AUTOSAR XML (schema 4-2-2)
package /STELLANTIS/EPT/ASWCs
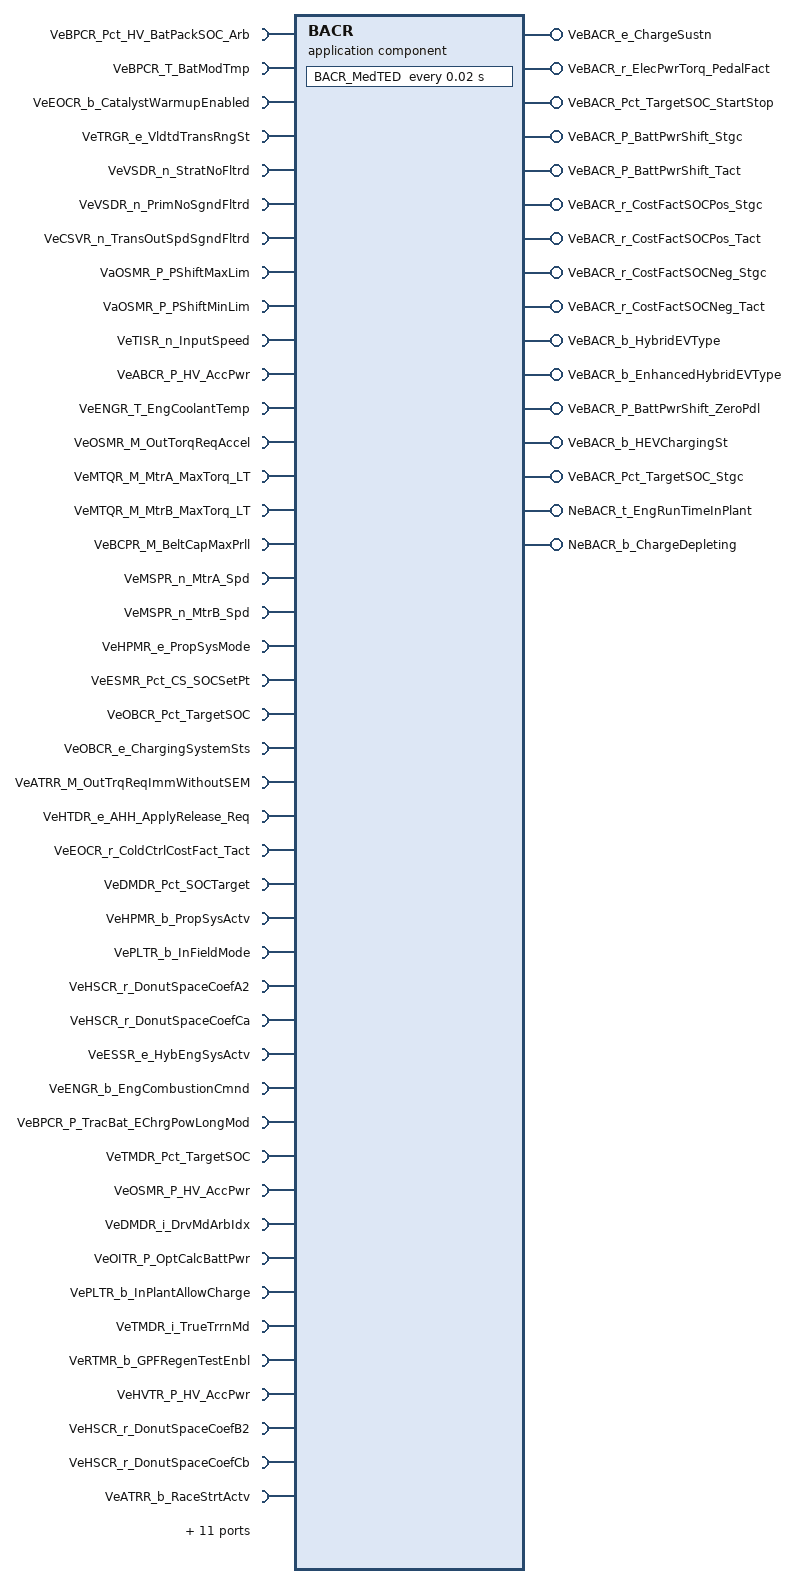
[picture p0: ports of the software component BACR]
  application sw component type BACR
    52 x require port:
      VeBPCR_Pct_HV_BatPackSOC_Arb: nonqueued-receiver-com-spec{data-element=Value, init-value=0}, required-interface=VeBPCR_Pct_HV_BatPackSOC_Arb
      VeBPCR_T_BatModTmp: nonqueued-receiver-com-spec{data-element=Value, init-value=0}, required-interface=VeBPCR_T_BatModTmp
      VeEOCR_b_CatalystWarmupEnabled: nonqueued-receiver-com-spec{data-element=Value, init-value=0}, required-interface=VeEOCR_b_CatalystWarmupEnabled
      VeTRGR_e_VldtdTransRngSt: nonqueued-receiver-com-spec{data-element=Value, init-value=CeTRGR_e_NoSelectionAvailable}, required-interface=VeTRGR_e_VldtdTransRngSt
      VeVSDR_n_StratNoFltrd: nonqueued-receiver-com-spec{data-element=Value, init-value=0}, required-interface=VeVSDR_n_StratNoFltrd
      VeVSDR_n_PrimNoSgndFltrd: nonqueued-receiver-com-spec{data-element=Value, init-value=0}, required-interface=VeVSDR_n_PrimNoSgndFltrd
      VeCSVR_n_TransOutSpdSgndFltrd: nonqueued-receiver-com-spec{data-element=Value, init-value=0}, required-interface=VeCSVR_n_TransOutSpdSgndFltrd
      VaOSMR_P_PShiftMaxLim: nonqueued-receiver-com-spec{data-element=Value, init-value=[0, 0]}, required-interface=VaOSMR_P_PShiftMaxLim
      VaOSMR_P_PShiftMinLim: nonqueued-receiver-com-spec{data-element=Value, init-value=[0, 0]}, required-interface=VaOSMR_P_PShiftMinLim
      VeTISR_n_InputSpeed: nonqueued-receiver-com-spec{data-element=Value, init-value=0}, required-interface=VeTISR_n_InputSpeed
      VeABCR_P_HV_AccPwr: nonqueued-receiver-com-spec{data-element=Value, init-value=0}, required-interface=VeABCR_P_HV_AccPwr
      VeENGR_T_EngCoolantTemp: nonqueued-receiver-com-spec{data-element=Value, init-value=0}, required-interface=VeENGR_T_EngCoolantTemp
      VeOSMR_M_OutTorqReqAccel: nonqueued-receiver-com-spec{data-element=Value, init-value=0}, required-interface=VeOSMR_M_OutTorqReqAccel
      VeMTQR_M_MtrA_MaxTorq_LT: nonqueued-receiver-com-spec{data-element=Value, init-value=0}, required-interface=VeMTQR_M_MtrA_MaxTorq_LT
      VeMTQR_M_MtrB_MaxTorq_LT: nonqueued-receiver-com-spec{data-element=Value, init-value=0}, required-interface=VeMTQR_M_MtrB_MaxTorq_LT
      VeBCPR_M_BeltCapMaxPrll: nonqueued-receiver-com-spec{data-element=Value, init-value=0}, required-interface=VeBCPR_M_BeltCapMaxPrll
      VeMSPR_n_MtrA_Spd: nonqueued-receiver-com-spec{data-element=Value, init-value=0}, required-interface=VeMSPR_n_MtrA_Spd
      VeMSPR_n_MtrB_Spd: nonqueued-receiver-com-spec{data-element=Value, init-value=0}, required-interface=VeMSPR_n_MtrB_Spd
      VeHPMR_e_PropSysMode: nonqueued-receiver-com-spec{data-element=Value, init-value=CeHPMR_e_Disabled}, required-interface=VeHPMR_e_PropSysMode
      VeESMR_Pct_CS_SOCSetPt: nonqueued-receiver-com-spec{data-element=Value, init-value=0}, required-interface=VeESMR_Pct_CS_SOCSetPt
      VeOBCR_Pct_TargetSOC: nonqueued-receiver-com-spec{data-element=Value, init-value=0}, required-interface=VeOBCR_Pct_TargetSOC
      VeOBCR_e_ChargingSystemSts: nonqueued-receiver-com-spec{data-element=Value, init-value=CeOBCR_e_NotCharging}, required-interface=VeOBCR_e_ChargingSystemSts
      VeATRR_M_OutTrqReqImmWithoutSEM: nonqueued-receiver-com-spec{data-element=Value, init-value=0}, required-interface=VeATRR_M_OutTrqReqImmWithoutSEM
      VeHTDR_e_AHH_ApplyRelease_Req: nonqueued-receiver-com-spec{data-element=Value, init-value=CeHTDR_e_AHH_Inactive}, required-interface=VeHTDR_e_AHH_ApplyRelease_Req
      VeEOCR_r_ColdCtrlCostFact_Tact: nonqueued-receiver-com-spec{data-element=Value, init-value=0}, required-interface=VeEOCR_r_ColdCtrlCostFact_Tact
      VeDMDR_Pct_SOCTarget: nonqueued-receiver-com-spec{data-element=Value, init-value=0}, required-interface=VeDMDR_Pct_SOCTarget
      VeHPMR_b_PropSysActv: nonqueued-receiver-com-spec{data-element=Value, init-value=0}, required-interface=VeHPMR_b_PropSysActv
      VePLTR_b_InFieldMode: nonqueued-receiver-com-spec{data-element=Value, init-value=0}, required-interface=VePLTR_b_InFieldMode
      VeHSCR_r_DonutSpaceCoefA2: nonqueued-receiver-com-spec{data-element=Value, init-value=0}, required-interface=VeHSCR_r_DonutSpaceCoefA2
      VeHSCR_r_DonutSpaceCoefCa: nonqueued-receiver-com-spec{data-element=Value, init-value=0}, required-interface=VeHSCR_r_DonutSpaceCoefCa
      VeESSR_e_HybEngSysActv: nonqueued-receiver-com-spec{data-element=Value, init-value=CeESSR_e_HybEngDisabled}, required-interface=VeESSR_e_HybEngSysActv
      VeENGR_b_EngCombustionCmnd: nonqueued-receiver-com-spec{data-element=Value, init-value=0}, required-interface=VeENGR_b_EngCombustionCmnd
      VeBPCR_P_TracBat_EChrgPowLongMod: nonqueued-receiver-com-spec{data-element=Value, init-value=0}, required-interface=VeBPCR_P_TracBat_EChrgPowLongMod
      VeTMDR_Pct_TargetSOC: nonqueued-receiver-com-spec{data-element=Value, init-value=0}, required-interface=VeTMDR_Pct_TargetSOC
      VeOSMR_P_HV_AccPwr: nonqueued-receiver-com-spec{data-element=Value, init-value=0}, required-interface=VeOSMR_P_HV_AccPwr
      VeDMDR_i_DrvMdArbIdx: nonqueued-receiver-com-spec{data-element=Value, init-value=0}, required-interface=VeDMDR_i_DrvMdArbIdx
      VeOITR_P_OptCalcBattPwr: nonqueued-receiver-com-spec{data-element=Value, init-value=0}, required-interface=VeOITR_P_OptCalcBattPwr
      VePLTR_b_InPlantAllowCharge: nonqueued-receiver-com-spec{data-element=Value, init-value=0}, required-interface=VePLTR_b_InPlantAllowCharge
      VeTMDR_i_TrueTrrnMd: nonqueued-receiver-com-spec{data-element=Value, init-value=0}, required-interface=VeTMDR_i_TrueTrrnMd
      VeRTMR_b_GPFRegenTestEnbl: nonqueued-receiver-com-spec{data-element=Value, init-value=0}, required-interface=VeRTMR_b_GPFRegenTestEnbl
      VeHVTR_P_HV_AccPwr: nonqueued-receiver-com-spec{data-element=Value, init-value=0}, required-interface=VeHVTR_P_HV_AccPwr
      VeHSCR_r_DonutSpaceCoefB2: nonqueued-receiver-com-spec{data-element=Value, init-value=0}, required-interface=VeHSCR_r_DonutSpaceCoefB2
      VeHSCR_r_DonutSpaceCoefCb: nonqueued-receiver-com-spec{data-element=Value, init-value=0}, required-interface=VeHSCR_r_DonutSpaceCoefCb
      VeATRR_b_RaceStrtActv: nonqueued-receiver-com-spec{data-element=Value, init-value=0}, required-interface=VeATRR_b_RaceStrtActv
      VeAPSR_Pct_AccelPedalEffPosition: nonqueued-receiver-com-spec{data-element=Value, init-value=0}, required-interface=VeAPSR_Pct_AccelPedalEffPosition
      VeVTXR_Pct_HVBattTgtSOC: nonqueued-receiver-com-spec{data-element=Value, init-value=0}, required-interface=VeVTXR_Pct_HVBattTgtSOC
      VeVTXR_e_PowerPanelMd: nonqueued-receiver-com-spec{data-element=Value, init-value=CeVTXR_e_DefaultMd}, required-interface=VeVTXR_e_PowerPanelMd
      VeFWDR_e_Tcase_Stat: nonqueued-receiver-com-spec{data-element=Value, init-value=CeFWDR_e_ShiftINProg}, required-interface=VeFWDR_e_Tcase_Stat
      VeRGNR_M_DrvIntndTotBrkOutTrq: nonqueued-receiver-com-spec{data-element=Value, init-value=0}, required-interface=VeRGNR_M_DrvIntndTotBrkOutTrq
      VeOITR_M_OutTorqReqModTactMin: nonqueued-receiver-com-spec{data-element=Value, init-value=0}, required-interface=VeOITR_M_OutTorqReqModTactMin
      VeOSMR_P_PoMaxLinConstrn: nonqueued-receiver-com-spec{data-element=Value, init-value=0}, required-interface=VeOSMR_P_PoMaxLinConstrn
      VeOITR_M_OutTorqReqModTactMax: nonqueued-receiver-com-spec{data-element=Value, init-value=0}, required-interface=VeOITR_M_OutTorqReqModTactMax
    14 x provide port:
      VeBACR_e_ChargeSustn: nonqueued-sender-com-spec{data-element=Value, init-value=CeBACR_e_ChargeSustaining}, provided-interface=VeBACR_e_ChargeSustn
      VeBACR_r_ElecPwrTorq_PedalFact: nonqueued-sender-com-spec{data-element=Value, init-value=0}, provided-interface=VeBACR_r_ElecPwrTorq_PedalFact
      VeBACR_Pct_TargetSOC_StartStop: nonqueued-sender-com-spec{data-element=Value, init-value=0}, provided-interface=VeBACR_Pct_TargetSOC_StartStop
      VeBACR_P_BattPwrShift_Stgc: nonqueued-sender-com-spec{data-element=Value, init-value=0}, provided-interface=VeBACR_P_BattPwrShift_Stgc
      VeBACR_P_BattPwrShift_Tact: nonqueued-sender-com-spec{data-element=Value, init-value=0}, provided-interface=VeBACR_P_BattPwrShift_Tact
      VeBACR_r_CostFactSOCPos_Stgc: nonqueued-sender-com-spec{data-element=Value, init-value=0}, provided-interface=VeBACR_r_CostFactSOCPos_Stgc
      VeBACR_r_CostFactSOCPos_Tact: nonqueued-sender-com-spec{data-element=Value, init-value=0}, provided-interface=VeBACR_r_CostFactSOCPos_Tact
      VeBACR_r_CostFactSOCNeg_Stgc: nonqueued-sender-com-spec{data-element=Value, init-value=0}, provided-interface=VeBACR_r_CostFactSOCNeg_Stgc
      VeBACR_r_CostFactSOCNeg_Tact: nonqueued-sender-com-spec{data-element=Value, init-value=0}, provided-interface=VeBACR_r_CostFactSOCNeg_Tact
      VeBACR_b_HybridEVType: nonqueued-sender-com-spec{data-element=Value, init-value=0}, provided-interface=VeBACR_b_HybridEVType
      VeBACR_b_EnhancedHybridEVType: nonqueued-sender-com-spec{data-element=Value, init-value=0}, provided-interface=VeBACR_b_EnhancedHybridEVType
      VeBACR_P_BattPwrShift_ZeroPdl: nonqueued-sender-com-spec{data-element=Value, init-value=0}, provided-interface=VeBACR_P_BattPwrShift_ZeroPdl
      VeBACR_b_HEVChargingSt: nonqueued-sender-com-spec{data-element=Value, init-value=0}, provided-interface=VeBACR_b_HEVChargingSt
      VeBACR_Pct_TargetSOC_Stgc: nonqueued-sender-com-spec{data-element=Value, init-value=0}, provided-interface=VeBACR_Pct_TargetSOC_Stgc
    require port NeBACR_t_EngRunTimeInPlant_Rx: nv-require-com-spec{init-value=0, variable=NeBACR_t_EngRunTimeInPlant}, required-interface=NeBACR_t_EngRunTimeInPlant
    require port NeBACR_b_ChargeDepleting_Rx: nv-require-com-spec{init-value=0, variable=NeBACR_b_ChargeDepleting}, required-interface=NeBACR_b_ChargeDepleting
    provide port NeBACR_t_EngRunTimeInPlant: nv-provide-com-spec{ram-block-init-value=0, variable=NeBACR_t_EngRunTimeInPlant}, provided-interface=NeBACR_t_EngRunTimeInPlant
    provide port NeBACR_b_ChargeDepleting: nv-provide-com-spec{ram-block-init-value=0, variable=NeBACR_b_ChargeDepleting}, provided-interface=NeBACR_b_ChargeDepleting
    require port KeOPTR_r_NiTiFctrMin: parameter-require-com-spec{init-value=KeOPTR_r_NiTiFctrMin_KeOPTR_r_NiTiFctrMin:0.00999999977648258, parameter=KeOPTR_r_NiTiFctrMin}, required-interface=KeOPTR_r_NiTiFctrMin
    behavior IB_BACR: data-type-mapping=msADTtoIDTMapping, handle-termination-and-restart=NO-SUPPORT
      timing event Event_MedTED: start-on-event=BACR_MedTED, period=0.02
      init event Event_BACR_ac_Init: start-on-event=BACR_ac_Init
      init event Event_PwrOn: start-on-event=BACR_PwrOn
      init event Event_PwrOff: start-on-event=BACR_PwrOff
      4 x runnable:
        BACR_ac_Init
          data-send-points:
            access OUT_VeBACR_e_ChargeSustn_Value: accessed-variable=VeBACR_e_ChargeSustn.Value
        BACR_PwrOn
          data-receive-point-by-arguments:
            access IN_NeBACR_b_ChargeDepleting_Rx_NeBACR_b_ChargeDepleting: accessed-variable=NeBACR_b_ChargeDepleting_Rx.NeBACR_b_ChargeDepleting
            access IN_NeBACR_t_EngRunTimeInPlant_Rx_NeBACR_t_EngRunTimeInPlant: accessed-variable=NeBACR_t_EngRunTimeInPlant_Rx.NeBACR_t_EngRunTimeInPlant
          data-send-points:
            14 x access:
              OUT_VeBACR_b_HybridEVType_Value: accessed-variable=VeBACR_b_HybridEVType.Value
              OUT_VeBACR_b_EnhancedHybridEVType_Value: accessed-variable=VeBACR_b_EnhancedHybridEVType.Value
              OUT_VeBACR_P_BattPwrShift_ZeroPdl_Value: accessed-variable=VeBACR_P_BattPwrShift_ZeroPdl.Value
              OUT_VeBACR_b_HEVChargingSt_Value: accessed-variable=VeBACR_b_HEVChargingSt.Value
              OUT_VeBACR_Pct_TargetSOC_Stgc_Value: accessed-variable=VeBACR_Pct_TargetSOC_Stgc.Value
              OUT_VeBACR_P_BattPwrShift_Stgc_Value: accessed-variable=VeBACR_P_BattPwrShift_Stgc.Value
              OUT_VeBACR_r_CostFactSOCPos_Stgc_Value: accessed-variable=VeBACR_r_CostFactSOCPos_Stgc.Value
              OUT_VeBACR_r_CostFactSOCNeg_Stgc_Value: accessed-variable=VeBACR_r_CostFactSOCNeg_Stgc.Value
              OUT_VeBACR_e_ChargeSustn_Value: accessed-variable=VeBACR_e_ChargeSustn.Value
              OUT_VeBACR_r_ElecPwrTorq_PedalFact_Value: accessed-variable=VeBACR_r_ElecPwrTorq_PedalFact.Value
              OUT_VeBACR_Pct_TargetSOC_StartStop_Value: accessed-variable=VeBACR_Pct_TargetSOC_StartStop.Value
              OUT_VeBACR_P_BattPwrShift_Tact_Value: accessed-variable=VeBACR_P_BattPwrShift_Tact.Value
              OUT_VeBACR_r_CostFactSOCPos_Tact_Value: accessed-variable=VeBACR_r_CostFactSOCPos_Tact.Value
              OUT_VeBACR_r_CostFactSOCNeg_Tact_Value: accessed-variable=VeBACR_r_CostFactSOCNeg_Tact.Value
        BACR_MedTED
          data-receive-point-by-arguments:
            52 x access:
              IN_VaOSMR_P_PShiftMaxLim_Value: accessed-variable=VaOSMR_P_PShiftMaxLim.Value
              IN_VaOSMR_P_PShiftMinLim_Value: accessed-variable=VaOSMR_P_PShiftMinLim.Value
              IN_VeABCR_P_HV_AccPwr_Value: accessed-variable=VeABCR_P_HV_AccPwr.Value
              IN_VeAPSR_Pct_AccelPedalEffPosition_Value: accessed-variable=VeAPSR_Pct_AccelPedalEffPosition.Value
              IN_VeATRR_M_OutTrqReqImmWithoutSEM_Value: accessed-variable=VeATRR_M_OutTrqReqImmWithoutSEM.Value
              IN_VeATRR_b_RaceStrtActv_Value: accessed-variable=VeATRR_b_RaceStrtActv.Value
              IN_VeBCPR_M_BeltCapMaxPrll_Value: accessed-variable=VeBCPR_M_BeltCapMaxPrll.Value
              IN_VeBPCR_P_TracBat_EChrgPowLongMod_Value: accessed-variable=VeBPCR_P_TracBat_EChrgPowLongMod.Value
              IN_VeBPCR_Pct_HV_BatPackSOC_Arb_Value: accessed-variable=VeBPCR_Pct_HV_BatPackSOC_Arb.Value
              IN_VeBPCR_T_BatModTmp_Value: accessed-variable=VeBPCR_T_BatModTmp.Value
              IN_VeCSVR_n_TransOutSpdSgndFltrd_Value: accessed-variable=VeCSVR_n_TransOutSpdSgndFltrd.Value
              IN_VeDMDR_Pct_SOCTarget_Value: accessed-variable=VeDMDR_Pct_SOCTarget.Value
              IN_VeDMDR_i_DrvMdArbIdx_Value: accessed-variable=VeDMDR_i_DrvMdArbIdx.Value
              IN_VeENGR_T_EngCoolantTemp_Value: accessed-variable=VeENGR_T_EngCoolantTemp.Value
              IN_VeENGR_b_EngCombustionCmnd_Value: accessed-variable=VeENGR_b_EngCombustionCmnd.Value
              IN_VeEOCR_b_CatalystWarmupEnabled_Value: accessed-variable=VeEOCR_b_CatalystWarmupEnabled.Value
              IN_VeEOCR_r_ColdCtrlCostFact_Tact_Value: accessed-variable=VeEOCR_r_ColdCtrlCostFact_Tact.Value
              IN_VeESMR_Pct_CS_SOCSetPt_Value: accessed-variable=VeESMR_Pct_CS_SOCSetPt.Value
              IN_VeESSR_e_HybEngSysActv_Value: accessed-variable=VeESSR_e_HybEngSysActv.Value
              IN_VeFWDR_e_Tcase_Stat_Value: accessed-variable=VeFWDR_e_Tcase_Stat.Value
              IN_VeHPMR_b_PropSysActv_Value: accessed-variable=VeHPMR_b_PropSysActv.Value
              IN_VeHPMR_e_PropSysMode_Value: accessed-variable=VeHPMR_e_PropSysMode.Value
              IN_VeHSCR_r_DonutSpaceCoefA2_Value: accessed-variable=VeHSCR_r_DonutSpaceCoefA2.Value
              IN_VeHSCR_r_DonutSpaceCoefB2_Value: accessed-variable=VeHSCR_r_DonutSpaceCoefB2.Value
              IN_VeHSCR_r_DonutSpaceCoefCa_Value: accessed-variable=VeHSCR_r_DonutSpaceCoefCa.Value
              IN_VeHSCR_r_DonutSpaceCoefCb_Value: accessed-variable=VeHSCR_r_DonutSpaceCoefCb.Value
              IN_VeHTDR_e_AHH_ApplyRelease_Req_Value: accessed-variable=VeHTDR_e_AHH_ApplyRelease_Req.Value
              IN_VeHVTR_P_HV_AccPwr_Value: accessed-variable=VeHVTR_P_HV_AccPwr.Value
              IN_VeMSPR_n_MtrA_Spd_Value: accessed-variable=VeMSPR_n_MtrA_Spd.Value
              IN_VeMSPR_n_MtrB_Spd_Value: accessed-variable=VeMSPR_n_MtrB_Spd.Value
              IN_VeMTQR_M_MtrA_MaxTorq_LT_Value: accessed-variable=VeMTQR_M_MtrA_MaxTorq_LT.Value
              IN_VeMTQR_M_MtrB_MaxTorq_LT_Value: accessed-variable=VeMTQR_M_MtrB_MaxTorq_LT.Value
              IN_VeOBCR_Pct_TargetSOC_Value: accessed-variable=VeOBCR_Pct_TargetSOC.Value
              IN_VeOBCR_e_ChargingSystemSts_Value: accessed-variable=VeOBCR_e_ChargingSystemSts.Value
              IN_VeOITR_M_OutTorqReqModTactMax_Value: accessed-variable=VeOITR_M_OutTorqReqModTactMax.Value
              IN_VeOITR_M_OutTorqReqModTactMin_Value: accessed-variable=VeOITR_M_OutTorqReqModTactMin.Value
              IN_VeOITR_P_OptCalcBattPwr_Value: accessed-variable=VeOITR_P_OptCalcBattPwr.Value
              IN_VeOSMR_M_OutTorqReqAccel_Value: accessed-variable=VeOSMR_M_OutTorqReqAccel.Value
              IN_VeOSMR_P_HV_AccPwr_Value: accessed-variable=VeOSMR_P_HV_AccPwr.Value
              IN_VeOSMR_P_PoMaxLinConstrn_Value: accessed-variable=VeOSMR_P_PoMaxLinConstrn.Value
              IN_VePLTR_b_InFieldMode_Value: accessed-variable=VePLTR_b_InFieldMode.Value
              IN_VePLTR_b_InPlantAllowCharge_Value: accessed-variable=VePLTR_b_InPlantAllowCharge.Value
              IN_VeRGNR_M_DrvIntndTotBrkOutTrq_Value: accessed-variable=VeRGNR_M_DrvIntndTotBrkOutTrq.Value
              IN_VeRTMR_b_GPFRegenTestEnbl_Value: accessed-variable=VeRTMR_b_GPFRegenTestEnbl.Value
              IN_VeTISR_n_InputSpeed_Value: accessed-variable=VeTISR_n_InputSpeed.Value
              IN_VeTMDR_Pct_TargetSOC_Value: accessed-variable=VeTMDR_Pct_TargetSOC.Value
              IN_VeTMDR_i_TrueTrrnMd_Value: accessed-variable=VeTMDR_i_TrueTrrnMd.Value
              IN_VeTRGR_e_VldtdTransRngSt_Value: accessed-variable=VeTRGR_e_VldtdTransRngSt.Value
              IN_VeVSDR_n_PrimNoSgndFltrd_Value: accessed-variable=VeVSDR_n_PrimNoSgndFltrd.Value
              IN_VeVSDR_n_StratNoFltrd_Value: accessed-variable=VeVSDR_n_StratNoFltrd.Value
              IN_VeVTXR_Pct_HVBattTgtSOC_Value: accessed-variable=VeVTXR_Pct_HVBattTgtSOC.Value
              IN_VeVTXR_e_PowerPanelMd_Value: accessed-variable=VeVTXR_e_PowerPanelMd.Value
          data-send-points:
            14 x access:
              OUT_VeBACR_b_HybridEVType_Value: accessed-variable=VeBACR_b_HybridEVType.Value
              OUT_VeBACR_b_EnhancedHybridEVType_Value: accessed-variable=VeBACR_b_EnhancedHybridEVType.Value
              OUT_VeBACR_P_BattPwrShift_ZeroPdl_Value: accessed-variable=VeBACR_P_BattPwrShift_ZeroPdl.Value
              OUT_VeBACR_b_HEVChargingSt_Value: accessed-variable=VeBACR_b_HEVChargingSt.Value
              OUT_VeBACR_Pct_TargetSOC_Stgc_Value: accessed-variable=VeBACR_Pct_TargetSOC_Stgc.Value
              OUT_VeBACR_P_BattPwrShift_Stgc_Value: accessed-variable=VeBACR_P_BattPwrShift_Stgc.Value
              OUT_VeBACR_r_CostFactSOCPos_Stgc_Value: accessed-variable=VeBACR_r_CostFactSOCPos_Stgc.Value
              OUT_VeBACR_r_CostFactSOCNeg_Stgc_Value: accessed-variable=VeBACR_r_CostFactSOCNeg_Stgc.Value
              OUT_VeBACR_e_ChargeSustn_Value: accessed-variable=VeBACR_e_ChargeSustn.Value
              OUT_VeBACR_r_ElecPwrTorq_PedalFact_Value: accessed-variable=VeBACR_r_ElecPwrTorq_PedalFact.Value
              OUT_VeBACR_Pct_TargetSOC_StartStop_Value: accessed-variable=VeBACR_Pct_TargetSOC_StartStop.Value
              OUT_VeBACR_P_BattPwrShift_Tact_Value: accessed-variable=VeBACR_P_BattPwrShift_Tact.Value
              OUT_VeBACR_r_CostFactSOCPos_Tact_Value: accessed-variable=VeBACR_r_CostFactSOCPos_Tact.Value
              OUT_VeBACR_r_CostFactSOCNeg_Tact_Value: accessed-variable=VeBACR_r_CostFactSOCNeg_Tact.Value
          parameter access CALPRM_KeOPTR_r_NiTiFctrMin_KeOPTR_r_NiTiFctrMin: accessed-parameter=KeOPTR_r_NiTiFctrMin.KeOPTR_r_NiTiFctrMin
        BACR_PwrOff
          data-send-points:
            access OUT_NeBACR_t_EngRunTimeInPlant_NeBACR_t_EngRunTimeInPlant: accessed-variable=NeBACR_t_EngRunTimeInPlant.NeBACR_t_EngRunTimeInPlant
            access OUT_NeBACR_b_ChargeDepleting_NeBACR_b_ChargeDepleting: accessed-variable=NeBACR_b_ChargeDepleting.NeBACR_b_ChargeDepleting
      variation point proxy Variant_BACR_1: category=CONDITION, condition-access=0
      variation point proxy Variant_BACR_OilDilutionPshiftEnbl: category=CONDITION, condition-access=0
